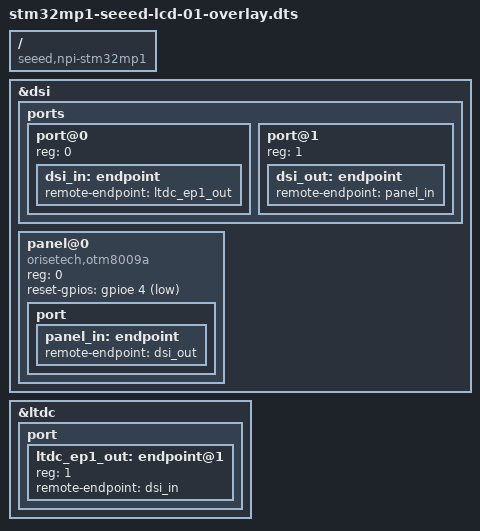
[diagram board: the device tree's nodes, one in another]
#include "dt-bindings/gpio/gpio.h"

/dts-v1/;
/plugin/;

/ {
    compatible = "seeed,npi-stm32mp1", "st,stm32mp157";

    fragment@1 {
        target = <&dsi>;
        __overlay__ {
        #address-cells = <1>;
        #size-cells = <0>;
        status = "okay";
        ports {
                #address-cells = <1>;
                #size-cells = <0>;

                port@0 {
                        reg = <0>;
                        dsi_in: endpoint {
                                remote-endpoint = <&ltdc_ep1_out>;
                        };
                };

                port@1 {
                        reg = <1>;
                        dsi_out: endpoint {
                                remote-endpoint = <&panel_in>;
                        };
                };
            };

        panel@0 {
                compatible = "orisetech,otm8009a";
                reg = <0>;
                reset-gpios = <&gpioe 4 GPIO_ACTIVE_LOW>;
                status = "okay";

                port {
                        panel_in: endpoint {
                                remote-endpoint = <&dsi_out>;
                        };
                };
            };
        };        
    };
    fragment@2 {
        target = <&ltdc>;
        __overlay__ {
            status = "okay";

            port {
                    #address-cells = <1>;
                    #size-cells = <0>;

                    ltdc_ep1_out: endpoint@1 {
                            reg = <1>;
                            remote-endpoint = <&dsi_in>;
                    };
            };
        };   
    };
};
